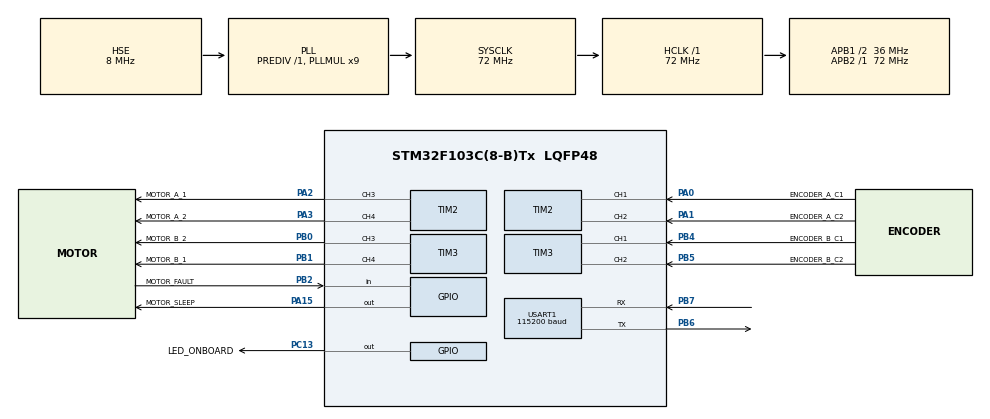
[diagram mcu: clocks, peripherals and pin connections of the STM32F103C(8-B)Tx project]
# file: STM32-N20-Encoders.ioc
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Mcu.Family=STM32F1
Mcu.Name=STM32F103C(8-B)Tx
Mcu.Package=LQFP48
NVIC.PriorityGroup=NVIC_PRIORITYGROUP_4
PA0-WKUP.GPIO_Label=ENCODER_A_C1
PA0-WKUP.Signal=S_TIM2_CH1_ETR
PA1.GPIO_Label=ENCODER_A_C2
PA1.Signal=S_TIM2_CH2
PA13.Mode=Trace_Asynchronous_SW
PA13.Signal=SYS_JTMS-SWDIO
PA14.Mode=Trace_Asynchronous_SW
PA14.Signal=SYS_JTCK-SWCLK
PA15.GPIO_Label=MOTOR_SLEEP
PA15.Signal=GPIO_Output
PA2.GPIO_Label=MOTOR_A_1
PA2.Signal=S_TIM2_CH3
PA3.GPIO_Label=MOTOR_A_2
PA3.Signal=S_TIM2_CH4
PB0.GPIO_Label=MOTOR_B_2
PB0.Signal=S_TIM3_CH3
PB1.GPIO_Label=MOTOR_B_1
PB1.Signal=S_TIM3_CH4
PB2.GPIO_Label=MOTOR_FAULT
PB2.Signal=GPIO_Input
PB3.Mode=Trace_Asynchronous_SW
PB3.Signal=SYS_JTDO-TRACESWO
PB4.GPIO_Label=ENCODER_B_C1
PB4.Signal=S_TIM3_CH1
PB5.GPIO_Label=ENCODER_B_C2
PB5.Signal=S_TIM3_CH2
PB6.Mode=Asynchronous
PB6.Signal=USART1_TX
PB7.Mode=Asynchronous
PB7.Signal=USART1_RX
PC13-TAMPER-RTC.GPIO_Label=LED_ONBOARD
PC13-TAMPER-RTC.Signal=GPIO_Output
PD0-OSC_IN.Mode=HSE-External-Oscillator
PD0-OSC_IN.Signal=RCC_OSC_IN
PD1-OSC_OUT.Mode=HSE-External-Oscillator
PD1-OSC_OUT.Signal=RCC_OSC_OUT
ProjectManager.HeapSize=0x200
ProjectManager.StackSize=0x400
ProjectManager.TargetToolchain=STM32CubeIDE
RCC.AHBFreq_Value=72000000
RCC.APB1CLKDivider=RCC_HCLK_DIV2
RCC.APB1Freq_Value=36000000
RCC.APB1TimFreq_Value=72000000
RCC.APB2Freq_Value=72000000
RCC.APB2TimFreq_Value=72000000
RCC.HCLKFreq_Value=72000000
RCC.PLLMUL=RCC_PLL_MUL9
RCC.PLLSourceVirtual=RCC_PLLSOURCE_HSE
RCC.SYSCLKFreq_VALUE=72000000
RCC.SYSCLKSource=RCC_SYSCLKSOURCE_PLLCLK
RCC.USBFreq_Value=72000000
SH.S_TIM2_CH1_ETR.0=TIM2_CH1,Encoder_Interface
SH.S_TIM2_CH2.0=TIM2_CH2,Encoder_Interface
SH.S_TIM2_CH3.0=TIM2_CH3,PWM Generation3 CH3
SH.S_TIM2_CH4.0=TIM2_CH4,PWM Generation4 CH4
SH.S_TIM3_CH1.0=TIM3_CH1,Encoder_Interface
SH.S_TIM3_CH2.0=TIM3_CH2,Encoder_Interface
SH.S_TIM3_CH3.0=TIM3_CH3,PWM Generation3 CH3
SH.S_TIM3_CH4.0=TIM3_CH4,PWM Generation4 CH4
TIM2.AutoReloadPreload=TIM_AUTORELOAD_PRELOAD_ENABLE
TIM2.Channel-PWM\ Generation3\ CH3=TIM_CHANNEL_3
TIM2.Channel-PWM\ Generation4\ CH4=TIM_CHANNEL_4
TIM2.EncoderMode=TIM_ENCODERMODE_TI12
TIM2.IC1Filter=10
TIM2.IC2Filter=10
TIM3.AutoReloadPreload=TIM_AUTORELOAD_PRELOAD_ENABLE
TIM3.Channel-PWM\ Generation3\ CH3=TIM_CHANNEL_3
TIM3.Channel-PWM\ Generation4\ CH4=TIM_CHANNEL_4
TIM3.EncoderMode=TIM_ENCODERMODE_TI12
TIM3.IC1Filter=10
TIM3.IC2Filter=10
USART1.BaudRate=115200
USART1.VirtualMode=VM_ASYNC
board=custom

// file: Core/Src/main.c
/* USER CODE BEGIN Header */
/**
  ******************************************************************************
  * @file           : main.c
  * @brief          : Main program body
  ******************************************************************************
  * @attention
  *
  * Copyright (c) 2024 STMicroelectronics.
  * All rights reserved.
  *
  * This software is licensed under terms that can be found in the LICENSE file
  * in the root directory of this software component.
  * If no LICENSE file comes with this software, it is provided AS-IS.
  *
  ******************************************************************************
  */
/* USER CODE END Header */
#include "main.h"
#include "tim.h"
#include "usart.h"
#include "gpio.h"

/* USER CODE BEGIN Includes */

#include "app.h"

/* USER CODE END Includes */

void SystemClock_Config(void);

int main(void)
{

  /* MCU Configuration--------------------------------------------------------*/

  /* Reset of all peripherals, Initializes the Flash interface and the Systick. */
  HAL_Init();

  /* Configure the system clock */
  SystemClock_Config();

  /* Initialize all configured peripherals */
  MX_GPIO_Init();
  MX_TIM2_Init();
  MX_TIM3_Init();
  MX_USART1_UART_Init();

  /* Infinite loop */
  /* USER CODE BEGIN WHILE */

  // Start application
  app_main();

    /* USER CODE END WHILE */

    /* USER CODE BEGIN 3 */

  // Should never get here
  while(1);

  /* USER CODE END 3 */
}

void SystemClock_Config(void)
{
  RCC_OscInitTypeDef RCC_OscInitStruct = {0};
  RCC_ClkInitTypeDef RCC_ClkInitStruct = {0};

  /** Initializes the RCC Oscillators according to the specified parameters
  * in the RCC_OscInitTypeDef structure.
  */
  RCC_OscInitStruct.OscillatorType = RCC_OSCILLATORTYPE_HSE;
  RCC_OscInitStruct.HSEState = RCC_HSE_ON;
  RCC_OscInitStruct.HSEPredivValue = RCC_HSE_PREDIV_DIV1;
  RCC_OscInitStruct.HSIState = RCC_HSI_ON;
  RCC_OscInitStruct.PLL.PLLState = RCC_PLL_ON;
  RCC_OscInitStruct.PLL.PLLSource = RCC_PLLSOURCE_HSE;
  RCC_OscInitStruct.PLL.PLLMUL = RCC_PLL_MUL9;
  if (HAL_RCC_OscConfig(&RCC_OscInitStruct) != HAL_OK)
  {
    Error_Handler();
  }

  /** Initializes the CPU, AHB and APB buses clocks
  */
  RCC_ClkInitStruct.ClockType = RCC_CLOCKTYPE_HCLK|RCC_CLOCKTYPE_SYSCLK
                              |RCC_CLOCKTYPE_PCLK1|RCC_CLOCKTYPE_PCLK2;
  RCC_ClkInitStruct.SYSCLKSource = RCC_SYSCLKSOURCE_PLLCLK;
  RCC_ClkInitStruct.AHBCLKDivider = RCC_SYSCLK_DIV1;
  RCC_ClkInitStruct.APB1CLKDivider = RCC_HCLK_DIV2;
  RCC_ClkInitStruct.APB2CLKDivider = RCC_HCLK_DIV1;

  if (HAL_RCC_ClockConfig(&RCC_ClkInitStruct, FLASH_LATENCY_2) != HAL_OK)
  {
    Error_Handler();
  }
}

void Error_Handler(void)
{
  __disable_irq();
  while (1)
  {
  }
}
